# MKV10Z7 register map
File version: 1.6
Registers are 32-bit, read-write, reset 0x0 unless marked. A register's access mark holds for its fields unless they carry their own. Offsets are from the block's base; [hi:lo] are bit positions; {n}, {i} and the like mark numbered series; 'fields as' and 'values as' point back to an identical list.

## CRC — Cyclic Redundancy Check
Base 0x40032000; register names take the prefix CRC_
0x00 DATALL 8-bit reset 0xFF (CRC view) — CRC_DATALL register.
  [7:0] DATALL — CRCLL stores the first 8 bits of the 32 bit DATA
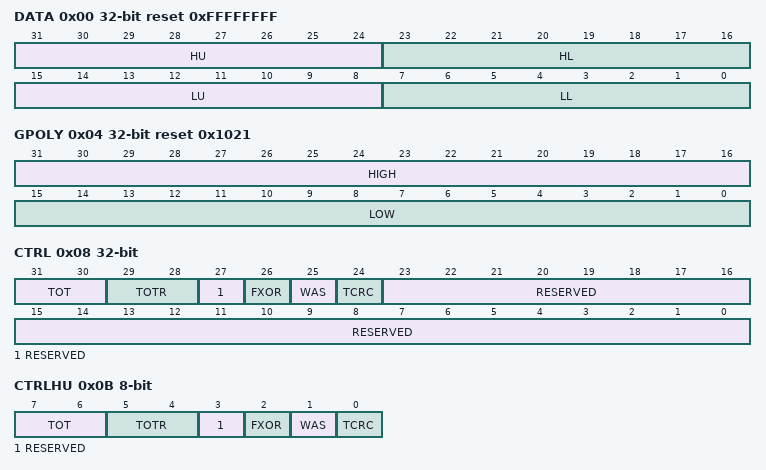
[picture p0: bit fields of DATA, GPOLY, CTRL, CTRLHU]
0x00 DATA reset 0xFFFFFFFF (CRC view) — CRC Data register
  [31:24] HU — CRC High Upper Byte
  [23:16] HL — CRC High Lower Byte
  [15:8] LU — CRC Low Upper Byte
  [7:0] LL — CRC Low Lower Byte
0x00 DATAL 16-bit reset 0xFFFF (CRC view) — CRC_DATAL register.
  [15:0] DATAL — DATAL stores the lower 16 bits of the 16/32 bit CRC
0x01 DATALU 8-bit reset 0xFF — CRC_DATALU register.
  [7:0] DATALU — DATALL stores the second 8 bits of the 32 bit CRC
0x02 DATAHL 8-bit reset 0xFF (CRC view) — CRC_DATAHL register.
  [7:0] DATAHL — DATAHL stores the third 8 bits of the 32 bit CRC
0x02 DATAH 16-bit reset 0xFFFF (CRC view) — CRC_DATAH register.
  [15:0] DATAH — DATAH stores the high 16 bits of the 16/32 bit CRC
0x03 DATAHU 8-bit reset 0xFF — CRC_DATAHU register.
  [7:0] DATAHU — DATAHU stores the fourth 8 bits of the 32 bit CRC
0x04 GPOLY reset 0x1021 (CRC view) — CRC Polynomial register
  [31:16] HIGH — High Polynominal Half-word
  [15:0] LOW — Low Polynominal Half-word
0x04 GPOLYLL 8-bit reset 0xFF (CRC view) — CRC_GPOLYLL register.
  [7:0] GPOLYLL — POLYLL stores the first 8 bits of the 32 bit CRC
0x04 GPOLYL 16-bit reset 0xFFFF (CRC view) — CRC_GPOLYL register.
  [15:0] GPOLYL — POLYL stores the lower 16 bits of the 16/32 bit CRC polynomial value
0x05 GPOLYLU 8-bit reset 0xFF — CRC_GPOLYLU register.
  [7:0] GPOLYLU — POLYLL stores the second 8 bits of the 32 bit CRC
0x06 GPOLYH 16-bit reset 0xFFFF (CRC view) — CRC_GPOLYH register.
  [15:0] GPOLYH — POLYH stores the high 16 bits of the 16/32 bit CRC polynomial value
0x06 GPOLYHL 8-bit reset 0xFF (CRC view) — CRC_GPOLYHL register.
  [7:0] GPOLYHL — POLYHL stores the third 8 bits of the 32 bit CRC
0x07 GPOLYHU 8-bit reset 0xFF — CRC_GPOLYHU register.
  [7:0] GPOLYHU — POLYHU stores the fourth 8 bits of the 32 bit CRC
0x08 CTRL — CRC Control register
  [31:30] TOT — Type Of Transpose For Writes
    0=No transposition; 1=Bits in bytes are transposed; bytes are not transposed; 2=Both bits in bytes and bytes are transposed; 3=Only bytes are transposed; no bits in a byte are transposed
  [29:28] TOTR — Type Of Transpose For Read
    values as TOT
  [27] RESERVED ro
  [26] FXOR — Complement Read Of CRC Data Register
    0=No XOR on reading; 1=Invert or complement the read value of the CRC Data register
  [25] WAS — Write CRC Data Register As Seed
    0=Writes to the CRC data register are data values; 1=Writes to the CRC data register are seed values
  [24] TCRC
    0=16-bit CRC protocol; 1=32-bit CRC protocol
  [23:0] RESERVED ro
0x0B CTRLHU 8-bit — CRC_CTRLHU register.
  [7:6] TOT
    0=No Transposition; 1=Bits in bytes are transposed, bytes are not transposed; 2=Both bits in bytes and bytes are transposed; 3=Only bytes are transposed; no bits in a byte are transposed
  [5:4] TOTR
    values as TOT
  [3] RESERVED ro
  [2] FXOR
    0=No XOR on reading; 1=Invert or complement the read value of CRC data register
  [1] WAS
    0=Writes to CRC data register are data values; 1=Writes to CRC data reguster are seed values
  [0] TCRC
    0=16-bit CRC protocol; 1=32-bit CRC protocol

## DAC0 — 12-Bit Digital-to-Analog Converter
Base 0x4003F000; register names take the prefix DAC0_
{0x0+2i} DAT{i}L (i=0..1) 8-bit — DAC Data Low Register
  [7:0] DATA0
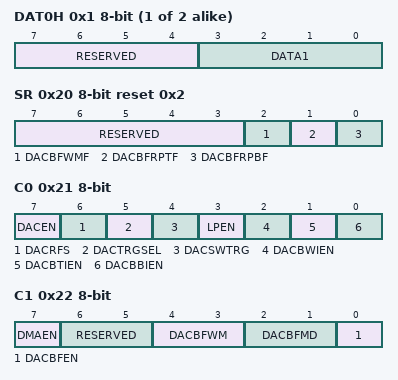
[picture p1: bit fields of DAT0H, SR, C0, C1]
{0x1+2i} DAT{i}H (i=0..1) 8-bit — DAC Data High Register
  [7:4] RESERVED ro, [3:0] DATA1
0x20 SR 8-bit reset 0x2 — DAC Status Register
  [7:3] RESERVED ro
  [2] DACBFWMF — DAC Buffer Watermark Flag
    0=The DAC buffer read pointer has not reached the watermark level; 1=The DAC buffer read pointer has reached the watermark level
  [1] DACBFRPTF — DAC Buffer Read Pointer Top Position Flag
    0=The DAC buffer read pointer is not zero; 1=The DAC buffer read pointer is zero
  [0] DACBFRPBF — DAC Buffer Read Pointer Bottom Position Flag
    0=The DAC buffer read pointer is not equal to C2[DACBFUP]; 1=The DAC buffer read pointer is equal to C2[DACBFUP]
0x21 C0 8-bit — DAC Control Register
  [7] DACEN — DAC Enable
    0=The DAC system is disabled; 1=The DAC system is enabled
  [6] DACRFS — DAC Reference Select
    0=The DAC selects DACREF_1 as the reference voltage; 1=The DAC selects DACREF_2 as the reference voltage
  [5] DACTRGSEL — DAC Trigger Select
    0=The DAC hardware trigger is selected; 1=The DAC software trigger is selected
  [4] DACSWTRG wo — DAC Software Trigger
    0=The DAC soft trigger is not valid; 1=The DAC soft trigger is valid
  [3] LPEN — DAC Low Power Control
    0=High-Power mode; 1=Low-Power mode
  [2] DACBWIEN — DAC Buffer Watermark Interrupt Enable
    0=The DAC buffer watermark interrupt is disabled; 1=The DAC buffer watermark interrupt is enabled
  [1] DACBTIEN — DAC Buffer Read Pointer Top Flag Interrupt Enable
    0=The DAC buffer read pointer top flag interrupt is disabled; 1=The DAC buffer read pointer top flag interrupt is enabled
  [0] DACBBIEN — DAC Buffer Read Pointer Bottom Flag Interrupt Enable
    0=The DAC buffer read pointer bottom flag interrupt is disabled; 1=The DAC buffer read pointer bottom flag interrupt is enabled
0x22 C1 8-bit — DAC Control Register 1
  [7] DMAEN — DMA Enable Select
    0=DMA is disabled; 1=DMA is enabled. When DMA is enabled, the DMA request will be generated by original interrupts. The interrupts will not be presented on this module at the same time.
  [6:5] RESERVED ro
  [4:3] DACBFWM — DAC Buffer Watermark Select
    0=1 word; 1=2 words; 2=3 words; 3=4 words
  [2:1] DACBFMD — DAC Buffer Work Mode Select
    0=Normal mode; 2=One-Time Scan mode
  [0] DACBFEN — DAC Buffer Enable
    0=Buffer read pointer is disabled. The converted data is always the first word of the buffer.; 1=Buffer read pointer is enabled. The converted data is the word that the read pointer points to. It means converted data can be from any word of the buffer.
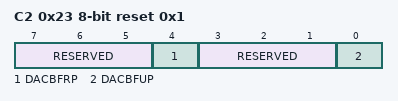
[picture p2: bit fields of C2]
0x23 C2 8-bit reset 0x1 — DAC Control Register 2
  [7:5] RESERVED ro
  [4] DACBFRP — DAC Buffer Read Pointer
  [3:1] RESERVED ro
  [0] DACBFUP — DAC Buffer Upper Limit
